# BL808 register map
File version: 0.1
Registers are access not given, no defined reset value unless marked. A register's access mark holds for its fields unless they carry their own. Offsets are from the block's base; [hi:lo] are bit positions.

## UART3
Base 0x30002000
Same registers: UART0 0x2000A000, UART1 0x2000A100
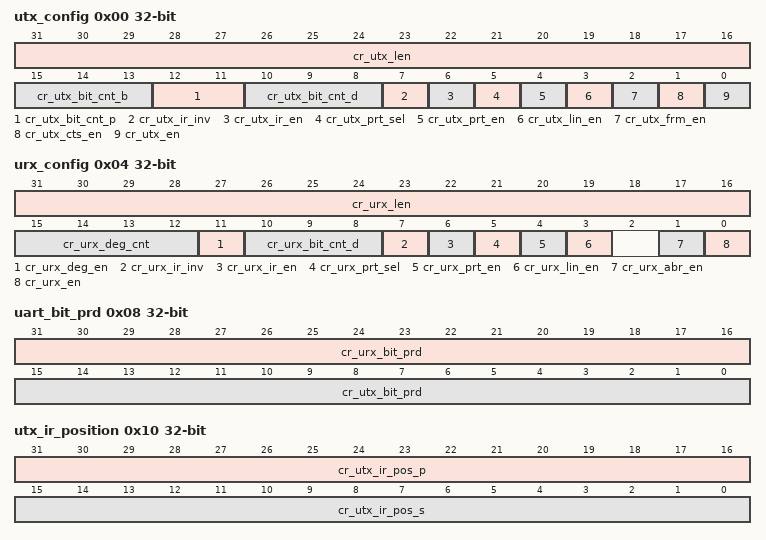
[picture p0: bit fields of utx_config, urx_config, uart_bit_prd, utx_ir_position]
0x00 utx_config rw
  [31:16] cr_utx_len — Length of UART TX data transfer (Unit: character/byte) (Don't-care if cr_utx_frm_en is enabled)
  [15:13] cr_utx_bit_cnt_b — UART TX BREAK bit count (for LIN protocol) Note: Additional 8 bit times will be added since LIN Break field requires at least 13 bit times
  [12:11] cr_utx_bit_cnt_p — UART TX STOP bit count (unit: 0.5 bit)
  [10:8] cr_utx_bit_cnt_d — UART TX DATA bit count for each character
  [7] cr_utx_ir_inv — Inverse signal of UART TX output in IR mode
  [6] cr_utx_ir_en — Enable signal of UART TX IR mode
  [5] cr_utx_prt_sel — Select signal of UART TX parity bit 1: Odd parity 0: Even parity
  [4] cr_utx_prt_en — Enable signal of UART TX parity bit
  [3] cr_utx_lin_en — Enable signal of UART TX LIN mode (LIN header will be sent before sending data)
  [2] cr_utx_frm_en — Enable signal of UART TX freerun mode (utx_end_int will be disabled)
  [1] cr_utx_cts_en — Enable signal of UART TX CTS flow control function
  [0] cr_utx_en — Enable signal of UART TX function Asserting this bit will trigger the transaction, and should be de-asserted after finish
0x04 urx_config
  [31:16] cr_urx_len rw — Length of UART RX data transfer (Unit: character/byte) urx_end_int will assert when this length is reached
  [15:12] cr_urx_deg_cnt rw — De-glitch function cycle count
  [11] cr_urx_deg_en rw — Enable signal of RXD input de-glitch function
  [10:8] cr_urx_bit_cnt_d rw — UART RX DATA bit count for each character
  [7] cr_urx_ir_inv rw — Inverse signal of UART RX input in IR mode
  [6] cr_urx_ir_en rw — Enable signal of UART RX IR mode
  [5] cr_urx_prt_sel rw — Select signal of UART RX parity bit 1: Odd parity 0: Even parity
  [4] cr_urx_prt_en rw — Enable signal of UART RX parity bit
  [3] cr_urx_lin_en rw — Enable signal of UART RX LIN mode (LIN header will be required and checked before receiving data)
  [1] cr_urx_abr_en rw — Enable signal of UART RX Auto Baud Rate detection function
  [0] cr_urx_en rw — Enable signal of UART RX function
0x08 uart_bit_prd rw
  [31:16] cr_urx_bit_prd — Period of each UART RX bit, related to baud rate
  [15:0] cr_utx_bit_prd — Period of each UART TX bit, related to baud rate
0x0C data_config
  [0] cr_uart_bit_inv rw — Bit-inverse signal for each data byte 0: Each byte is sent out LSB-first 1: Each byte is sent out MSB-first
0x10 utx_ir_position rw
  [31:16] cr_utx_ir_pos_p — STOP position of UART TX IR pulse
  [15:0] cr_utx_ir_pos_s — START position of UART TX IR pulse
0x14 urx_ir_position
  [15:0] cr_urx_ir_pos_s rw — START position of UART RXD pulse recovered from IR signal
0x18 urx_rto_timer
  [7:0] cr_urx_rto_value rw — Time-out value for triggering RTO interrupt (unit: bit time)
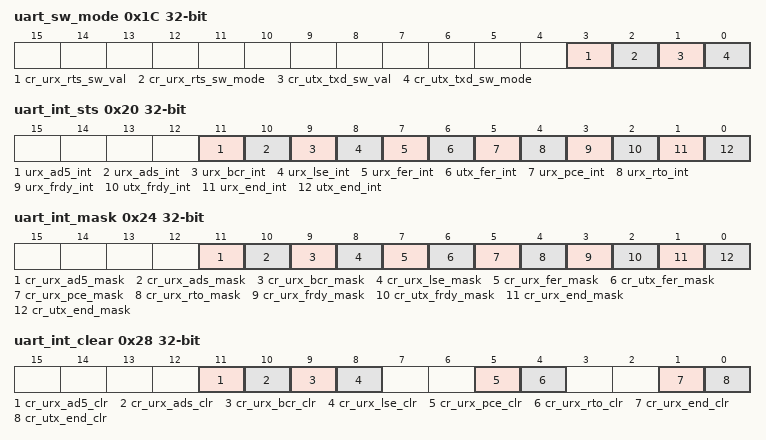
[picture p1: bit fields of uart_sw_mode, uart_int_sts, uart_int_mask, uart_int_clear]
0x1C uart_sw_mode
  [3] cr_urx_rts_sw_val rw — UART RX RTS output SW control value
  [2] cr_urx_rts_sw_mode rw — UART RX RTS output SW control mode
  [1] cr_utx_txd_sw_val rw — UART TX TXD output SW control value
  [0] cr_utx_txd_sw_mode rw — UART TX TXD output SW control mode
0x20 uart_int_sts
  [11] urx_ad5_int ro — UART RX ABR Detection finish interrupt using codeword 0x55
  [10] urx_ads_int ro — UART RX ABR Detection finish interrupt using START bit
  [9] urx_bcr_int ro — UART RX byte count reached interrupt
  [8] urx_lse_int ro — UART RX LIN mode sync field error interrupt
  [7] urx_fer_int ro — UART RX FIFO error interrupt, auto-cleared when FIFO overflow/underflow error flag is cleared
  [6] utx_fer_int ro — UART TX FIFO error interrupt, auto-cleared when FIFO overflow/underflow error flag is cleared
  [5] urx_pce_int ro — UART RX parity check error interrupt
  [4] urx_rto_int ro — UART RX Time-out interrupt
  [3] urx_frdy_int ro — UART RX FIFO ready (rx_fifo_cnt > rx_fifo_th) interrupt, auto-cleared when data is popped
  [2] utx_frdy_int ro — UART TX FIFO ready (tx_fifo_cnt > tx_fifo_th) interrupt, auto-cleared when data is pushed
  [1] urx_end_int ro — UART RX transfer end interrupt (set according to cr_urx_len)
  [0] utx_end_int ro — UART TX transfer end interrupt (set according to cr_utx_len)
0x24 uart_int_mask
  [11] cr_urx_ad5_mask rw — Interrupt mask of urx_ad5_int
  [10] cr_urx_ads_mask rw — Interrupt mask of urx_ads_int
  [9] cr_urx_bcr_mask rw — Interrupt mask of urx_bcr_int
  [8] cr_urx_lse_mask rw — Interrupt mask of urx_lse_int
  [7] cr_urx_fer_mask rw — Interrupt mask of urx_fer_int
  [6] cr_utx_fer_mask rw — Interrupt mask of utx_fer_int
  [5] cr_urx_pce_mask rw — Interrupt mask of urx_pce_int
  [4] cr_urx_rto_mask rw — Interrupt mask of urx_rto_int
  [3] cr_urx_frdy_mask rw — Interrupt mask of urx_frdy_int
  [2] cr_utx_frdy_mask rw — Interrupt mask of utx_frdy_int
  [1] cr_urx_end_mask rw — Interrupt mask of urx_end_int
  [0] cr_utx_end_mask rw — Interrupt mask of utx_end_int
0x28 uart_int_clear
  [11] cr_urx_ad5_clr write-once — Interrupt clear of urx_ad5_int
  [10] cr_urx_ads_clr write-once — Interrupt clear of urx_ads_int
  [9] cr_urx_bcr_clr write-once — Interrupt clear of urx_bcr_int
  [8] cr_urx_lse_clr write-once — Interrupt clear of urx_lse_int
  [5] cr_urx_pce_clr write-once — Interrupt clear of urx_pce_int
  [4] cr_urx_rto_clr write-once — Interrupt clear of urx_rto_int
  [1] cr_urx_end_clr write-once — Interrupt clear of urx_end_int
  [0] cr_utx_end_clr write-once — Interrupt clear of utx_end_int
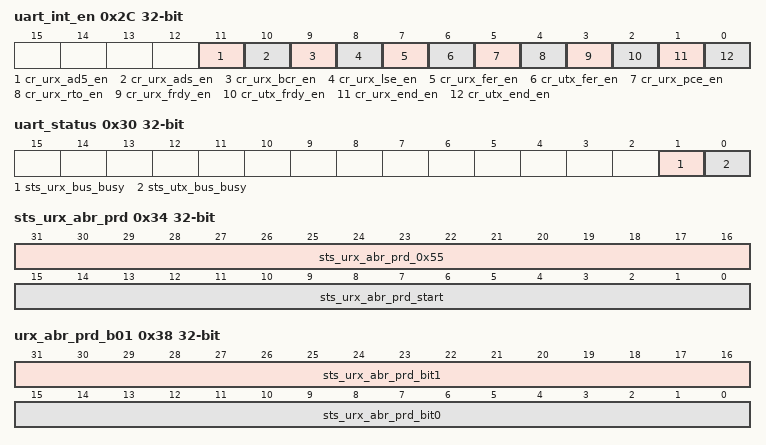
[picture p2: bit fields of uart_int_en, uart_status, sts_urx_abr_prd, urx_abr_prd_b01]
0x2C uart_int_en
  [11] cr_urx_ad5_en rw — Interrupt enable of urx_ad5_int
  [10] cr_urx_ads_en rw — Interrupt enable of urx_ads_int
  [9] cr_urx_bcr_en rw — Interrupt enable of urx_bcr_int
  [8] cr_urx_lse_en rw — Interrupt enable of urx_lse_int
  [7] cr_urx_fer_en rw — Interrupt enable of urx_fer_int
  [6] cr_utx_fer_en rw — Interrupt enable of utx_fer_int
  [5] cr_urx_pce_en rw — Interrupt enable of urx_pce_int
  [4] cr_urx_rto_en rw — Interrupt enable of urx_rto_int
  [3] cr_urx_frdy_en rw — Interrupt enable of urx_frdy_int
  [2] cr_utx_frdy_en rw — Interrupt enable of utx_frdy_int
  [1] cr_urx_end_en rw — Interrupt enable of urx_end_int
  [0] cr_utx_end_en rw — Interrupt enable of utx_end_int
0x30 uart_status
  [1] sts_urx_bus_busy ro — Indicator of UART RX bus busy
  [0] sts_utx_bus_busy ro — Indicator of UART TX bus busy
0x34 sts_urx_abr_prd ro
  [31:16] sts_urx_abr_prd_0x55 — Bit period of Auto Baud Rate detection using codeword 0x55
  [15:0] sts_urx_abr_prd_start — Bit period of Auto Baud Rate detection using START bit
0x38 urx_abr_prd_b01 ro
  [31:16] sts_urx_abr_prd_bit1 — Bit period of Auto Baud Rate detection - bit[1]
  [15:0] sts_urx_abr_prd_bit0 — Bit period of Auto Baud Rate detection - bit[0]
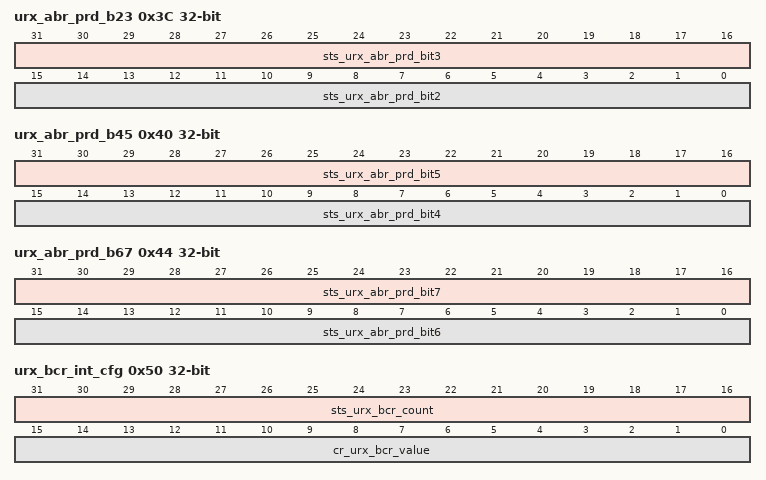
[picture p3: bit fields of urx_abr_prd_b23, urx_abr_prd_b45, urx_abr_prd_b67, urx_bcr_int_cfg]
0x3C urx_abr_prd_b23 ro
  [31:16] sts_urx_abr_prd_bit3 — Bit period of Auto Baud Rate detection - bit[3]
  [15:0] sts_urx_abr_prd_bit2 — Bit period of Auto Baud Rate detection - bit[2]
0x40 urx_abr_prd_b45 ro
  [31:16] sts_urx_abr_prd_bit5 — Bit period of Auto Baud Rate detection - bit[5]
  [15:0] sts_urx_abr_prd_bit4 — Bit period of Auto Baud Rate detection - bit[4]
0x44 urx_abr_prd_b67 ro
  [31:16] sts_urx_abr_prd_bit7 — Bit period of Auto Baud Rate detection - bit[7]
  [15:0] sts_urx_abr_prd_bit6 — Bit period of Auto Baud Rate detection - bit[6]
0x48 urx_abr_pw_tol
  [7:0] cr_urx_abr_pw_tol rw — Auto Baud Rate detection pulse-width tolerance for using codeword 0x55
0x50 urx_bcr_int_cfg access per field
  [31:16] sts_urx_bcr_count ro — Current byte count of urx_bcr_int counter, auto-cleared bt cr_urx_bcr_clr
  [15:0] cr_urx_bcr_value rw — Byte count setting for urx_bcr_int counter
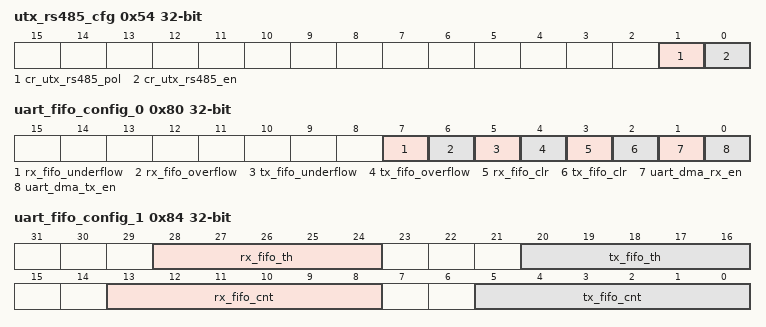
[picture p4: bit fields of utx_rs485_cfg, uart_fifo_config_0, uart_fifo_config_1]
0x54 utx_rs485_cfg
  [1] cr_utx_rs485_pol rw — DE pin polarity in RS-485 transceiver mode 1'b0: DE is active-low 1'b1: DE is active-high
  [0] cr_utx_rs485_en rw — Enable signal for RS-485 transceiver mode 1'b0: Disabled, normal UART 1'b1: Enabled, IO is connected to RS-485 transceiver and RTS_O becomes DE function
0x80 uart_fifo_config_0
  [7] rx_fifo_underflow ro — Underflow flag of RX FIFO, can be cleared by rx_fifo_clr
  [6] rx_fifo_overflow ro — Overflow flag of RX FIFO, can be cleared by rx_fifo_clr
  [5] tx_fifo_underflow ro — Underflow flag of TX FIFO, can be cleared by tx_fifo_clr
  [4] tx_fifo_overflow ro — Overflow flag of TX FIFO, can be cleared by tx_fifo_clr
  [3] rx_fifo_clr write-once — Clear signal of RX FIFO
  [2] tx_fifo_clr write-once — Clear signal of TX FIFO
  [1] uart_dma_rx_en rw — Enable signal of dma_rx_req/ack interface
  [0] uart_dma_tx_en rw — Enable signal of dma_tx_req/ack interface
0x84 uart_fifo_config_1
  [28:24] rx_fifo_th rw — RX FIFO threshold, dma_rx_req will not be asserted if rx_fifo_cnt is less than this value
  [20:16] tx_fifo_th rw — TX FIFO threshold, dma_tx_req will not be asserted if tx_fifo_cnt is less than this value
  [13:8] rx_fifo_cnt ro — RX FIFO available count
  [5:0] tx_fifo_cnt ro — TX FIFO available count
0x88 uart_fifo_wdata
  [7:0] uart_fifo_wdata wo
0x8C uart_fifo_rdata
  [7:0] uart_fifo_rdata ro
